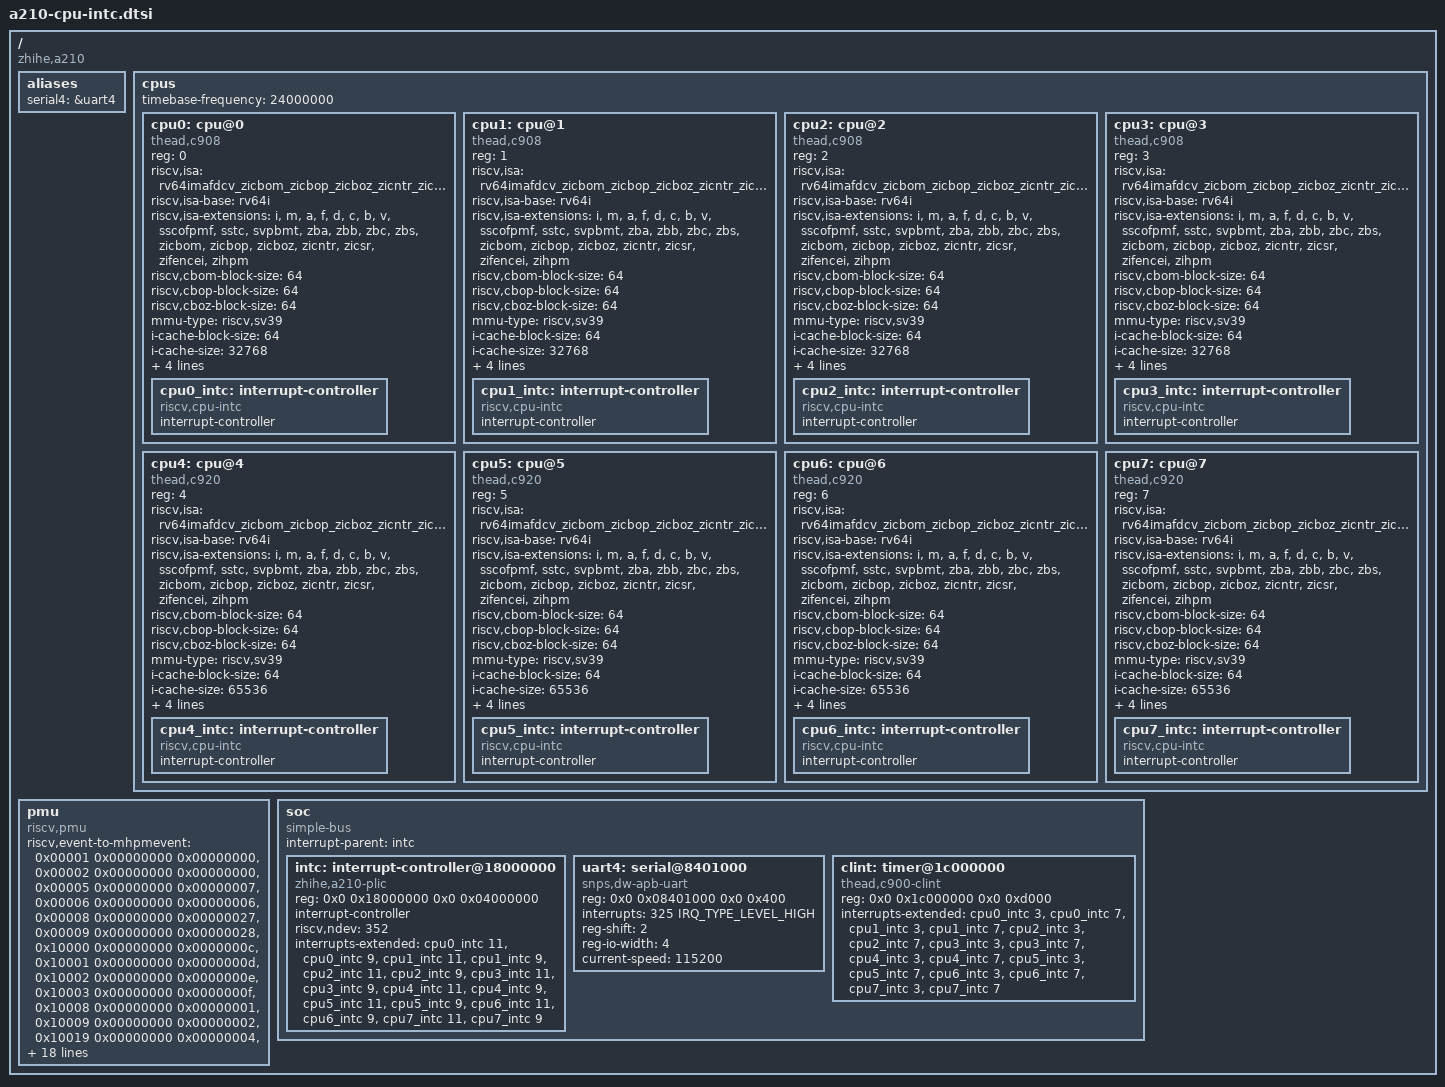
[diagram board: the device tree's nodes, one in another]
// SPDX-License-Identifier: (GPL-2.0-only OR BSD-2-Clause)
/*
 * Common A210 CPU/interrupt description for U-Boot and OpenSBI.
 * Hardware values follow the A210 Linux DTS; bootph tags are U-Boot-only.
 */
#include <dt-bindings/interrupt-controller/irq.h>

/ {
	compatible = "zhihe,a210";
	#address-cells = <2>;
	#size-cells = <2>;

	aliases {
		serial4 = &uart4;
	};

	cpus: cpus {
		#address-cells = <1>;
		#size-cells = <0>;
		timebase-frequency = <24000000>;
		bootph-pre-ram;

		cpu0: cpu@0 {
			device_type = "cpu";
			reg = <0>;
			compatible = "thead,c908", "riscv";
			/* Legacy U-Boot CPU code still reads riscv,isa. */
			riscv,isa = "rv64imafdcv_zicbom_zicbop_zicboz_zicntr_zicsr_zifencei_zihpm_zba_zbb_zbc_zbs_sscofpmf_sstc_svpbmt";
			riscv,isa-base = "rv64i";
			riscv,isa-extensions = "i", "m", "a", "f", "d", "c", "b", "v",
				"sscofpmf", "sstc", "svpbmt", "zba", "zbb", "zbc", "zbs",
				"zicbom", "zicbop", "zicboz", "zicntr", "zicsr",
				"zifencei", "zihpm";
			riscv,cbom-block-size = <64>;
			riscv,cbop-block-size = <64>;
			riscv,cboz-block-size = <64>;
			mmu-type = "riscv,sv39";
			i-cache-block-size = <64>;
			i-cache-size = <32768>;
			i-cache-sets = <256>;
			d-cache-block-size = <64>;
			d-cache-size = <32768>;
			d-cache-sets = <256>;
			status = "okay";
			bootph-pre-ram;

			cpu0_intc: interrupt-controller {
				compatible = "riscv,cpu-intc";
				#interrupt-cells = <1>;
				interrupt-controller;
				bootph-pre-ram;
			};
		};

		cpu1: cpu@1 {
			device_type = "cpu";
			reg = <1>;
			compatible = "thead,c908", "riscv";
			/* Legacy U-Boot CPU code still reads riscv,isa. */
			riscv,isa = "rv64imafdcv_zicbom_zicbop_zicboz_zicntr_zicsr_zifencei_zihpm_zba_zbb_zbc_zbs_sscofpmf_sstc_svpbmt";
			riscv,isa-base = "rv64i";
			riscv,isa-extensions = "i", "m", "a", "f", "d", "c", "b", "v",
				"sscofpmf", "sstc", "svpbmt", "zba", "zbb", "zbc", "zbs",
				"zicbom", "zicbop", "zicboz", "zicntr", "zicsr",
				"zifencei", "zihpm";
			riscv,cbom-block-size = <64>;
			riscv,cbop-block-size = <64>;
			riscv,cboz-block-size = <64>;
			mmu-type = "riscv,sv39";
			i-cache-block-size = <64>;
			i-cache-size = <32768>;
			i-cache-sets = <256>;
			d-cache-block-size = <64>;
			d-cache-size = <32768>;
			d-cache-sets = <256>;
			status = "okay";
			bootph-pre-ram;

			cpu1_intc: interrupt-controller {
				compatible = "riscv,cpu-intc";
				#interrupt-cells = <1>;
				interrupt-controller;
				bootph-pre-ram;
			};
		};

		cpu2: cpu@2 {
			device_type = "cpu";
			reg = <2>;
			compatible = "thead,c908", "riscv";
			/* Legacy U-Boot CPU code still reads riscv,isa. */
			riscv,isa = "rv64imafdcv_zicbom_zicbop_zicboz_zicntr_zicsr_zifencei_zihpm_zba_zbb_zbc_zbs_sscofpmf_sstc_svpbmt";
			riscv,isa-base = "rv64i";
			riscv,isa-extensions = "i", "m", "a", "f", "d", "c", "b", "v",
				"sscofpmf", "sstc", "svpbmt", "zba", "zbb", "zbc", "zbs",
				"zicbom", "zicbop", "zicboz", "zicntr", "zicsr",
				"zifencei", "zihpm";
			riscv,cbom-block-size = <64>;
			riscv,cbop-block-size = <64>;
			riscv,cboz-block-size = <64>;
			mmu-type = "riscv,sv39";
			i-cache-block-size = <64>;
			i-cache-size = <32768>;
			i-cache-sets = <256>;
			d-cache-block-size = <64>;
			d-cache-size = <32768>;
			d-cache-sets = <256>;
			status = "okay";
			bootph-pre-ram;

			cpu2_intc: interrupt-controller {
				compatible = "riscv,cpu-intc";
				#interrupt-cells = <1>;
				interrupt-controller;
				bootph-pre-ram;
			};
		};

		cpu3: cpu@3 {
			device_type = "cpu";
			reg = <3>;
			compatible = "thead,c908", "riscv";
			/* Legacy U-Boot CPU code still reads riscv,isa. */
			riscv,isa = "rv64imafdcv_zicbom_zicbop_zicboz_zicntr_zicsr_zifencei_zihpm_zba_zbb_zbc_zbs_sscofpmf_sstc_svpbmt";
			riscv,isa-base = "rv64i";
			riscv,isa-extensions = "i", "m", "a", "f", "d", "c", "b", "v",
				"sscofpmf", "sstc", "svpbmt", "zba", "zbb", "zbc", "zbs",
				"zicbom", "zicbop", "zicboz", "zicntr", "zicsr",
				"zifencei", "zihpm";
			riscv,cbom-block-size = <64>;
			riscv,cbop-block-size = <64>;
			riscv,cboz-block-size = <64>;
			mmu-type = "riscv,sv39";
			i-cache-block-size = <64>;
			i-cache-size = <32768>;
			i-cache-sets = <256>;
			d-cache-block-size = <64>;
			d-cache-size = <32768>;
			d-cache-sets = <256>;
			status = "okay";
			bootph-pre-ram;

			cpu3_intc: interrupt-controller {
				compatible = "riscv,cpu-intc";
				#interrupt-cells = <1>;
				interrupt-controller;
				bootph-pre-ram;
			};
		};

		cpu4: cpu@4 {
			device_type = "cpu";
			reg = <4>;
			compatible = "thead,c920", "riscv";
			/* Legacy U-Boot CPU code still reads riscv,isa. */
			riscv,isa = "rv64imafdcv_zicbom_zicbop_zicboz_zicntr_zicsr_zifencei_zihpm_zba_zbb_zbc_zbs_sscofpmf_sstc_svpbmt";
			riscv,isa-base = "rv64i";
			riscv,isa-extensions = "i", "m", "a", "f", "d", "c", "b", "v",
				"sscofpmf", "sstc", "svpbmt", "zba", "zbb", "zbc", "zbs",
				"zicbom", "zicbop", "zicboz", "zicntr", "zicsr",
				"zifencei", "zihpm";
			riscv,cbom-block-size = <64>;
			riscv,cbop-block-size = <64>;
			riscv,cboz-block-size = <64>;
			mmu-type = "riscv,sv39";
			i-cache-block-size = <64>;
			i-cache-size = <65536>;
			i-cache-sets = <512>;
			d-cache-block-size = <64>;
			d-cache-size = <65536>;
			d-cache-sets = <512>;
			status = "okay";
			bootph-pre-ram;

			cpu4_intc: interrupt-controller {
				compatible = "riscv,cpu-intc";
				#interrupt-cells = <1>;
				interrupt-controller;
				bootph-pre-ram;
			};
		};

		cpu5: cpu@5 {
			device_type = "cpu";
			reg = <5>;
			compatible = "thead,c920", "riscv";
			/* Legacy U-Boot CPU code still reads riscv,isa. */
			riscv,isa = "rv64imafdcv_zicbom_zicbop_zicboz_zicntr_zicsr_zifencei_zihpm_zba_zbb_zbc_zbs_sscofpmf_sstc_svpbmt";
			riscv,isa-base = "rv64i";
			riscv,isa-extensions = "i", "m", "a", "f", "d", "c", "b", "v",
				"sscofpmf", "sstc", "svpbmt", "zba", "zbb", "zbc", "zbs",
				"zicbom", "zicbop", "zicboz", "zicntr", "zicsr",
				"zifencei", "zihpm";
			riscv,cbom-block-size = <64>;
			riscv,cbop-block-size = <64>;
			riscv,cboz-block-size = <64>;
			mmu-type = "riscv,sv39";
			i-cache-block-size = <64>;
			i-cache-size = <65536>;
			i-cache-sets = <512>;
			d-cache-block-size = <64>;
			d-cache-size = <65536>;
			d-cache-sets = <512>;
			status = "okay";
			bootph-pre-ram;

			cpu5_intc: interrupt-controller {
				compatible = "riscv,cpu-intc";
				#interrupt-cells = <1>;
				interrupt-controller;
				bootph-pre-ram;
			};
		};

		cpu6: cpu@6 {
			device_type = "cpu";
			reg = <6>;
			compatible = "thead,c920", "riscv";
			/* Legacy U-Boot CPU code still reads riscv,isa. */
			riscv,isa = "rv64imafdcv_zicbom_zicbop_zicboz_zicntr_zicsr_zifencei_zihpm_zba_zbb_zbc_zbs_sscofpmf_sstc_svpbmt";
			riscv,isa-base = "rv64i";
			riscv,isa-extensions = "i", "m", "a", "f", "d", "c", "b", "v",
				"sscofpmf", "sstc", "svpbmt", "zba", "zbb", "zbc", "zbs",
				"zicbom", "zicbop", "zicboz", "zicntr", "zicsr",
				"zifencei", "zihpm";
			riscv,cbom-block-size = <64>;
			riscv,cbop-block-size = <64>;
			riscv,cboz-block-size = <64>;
			mmu-type = "riscv,sv39";
			i-cache-block-size = <64>;
			i-cache-size = <65536>;
			i-cache-sets = <512>;
			d-cache-block-size = <64>;
			d-cache-size = <65536>;
			d-cache-sets = <512>;
			status = "okay";
			bootph-pre-ram;

			cpu6_intc: interrupt-controller {
				compatible = "riscv,cpu-intc";
				#interrupt-cells = <1>;
				interrupt-controller;
				bootph-pre-ram;
			};
		};

		cpu7: cpu@7 {
			device_type = "cpu";
			reg = <7>;
			compatible = "thead,c920", "riscv";
			/* Legacy U-Boot CPU code still reads riscv,isa. */
			riscv,isa = "rv64imafdcv_zicbom_zicbop_zicboz_zicntr_zicsr_zifencei_zihpm_zba_zbb_zbc_zbs_sscofpmf_sstc_svpbmt";
			riscv,isa-base = "rv64i";
			riscv,isa-extensions = "i", "m", "a", "f", "d", "c", "b", "v",
				"sscofpmf", "sstc", "svpbmt", "zba", "zbb", "zbc", "zbs",
				"zicbom", "zicbop", "zicboz", "zicntr", "zicsr",
				"zifencei", "zihpm";
			riscv,cbom-block-size = <64>;
			riscv,cbop-block-size = <64>;
			riscv,cboz-block-size = <64>;
			mmu-type = "riscv,sv39";
			i-cache-block-size = <64>;
			i-cache-size = <65536>;
			i-cache-sets = <512>;
			d-cache-block-size = <64>;
			d-cache-size = <65536>;
			d-cache-sets = <512>;
			status = "okay";
			bootph-pre-ram;

			cpu7_intc: interrupt-controller {
				compatible = "riscv,cpu-intc";
				#interrupt-cells = <1>;
				interrupt-controller;
				bootph-pre-ram;
			};
		};
	};

	pmu {
		compatible = "riscv,pmu";
		riscv,event-to-mhpmevent =
			/* PMU_HW_CPU_CYCLES:1 */
			<0x00001 0x00000000 0x00000000>,
			/* PMU_HW_INSTRUCTIONS:2 */
			<0x00002 0x00000000 0x00000000>,
			/* PMU_HW_CACHE_REFERENCES:3 */
			/* PMU_HW_CACHE_MISSES:4 */
			/* PMU_HW_BRANCH_INSTRUCTIONS:5 */
			<0x00005 0x00000000 0x00000007>,
			/* PMU_HW_BRANCH_MISSES:6 */
			<0x00006 0x00000000 0x00000006>,
			/* PMU_HW_BUS_CYCLES:7 */
			/* PMU_HW_STALLED_CYCLES_FRONTEND:8 */
			<0x00008 0x00000000 0x00000027>,
			/* PMU_HW_STALLED_CYCLES_BACKEND:9 */
			<0x00009 0x00000000 0x00000028>,
			/* PMU_HW_REF_CPU_CYCLES:10 */
			/* L1D_READ_ACCESS:0x10000 */
			<0x10000 0x00000000 0x0000000c>,
			/* L1D_READ_MISS:0x10001 */
			<0x10001 0x00000000 0x0000000d>,
			/* L1D_WRITE_ACCESS:0x10002 */
			<0x10002 0x00000000 0x0000000e>,
			/* L1D_WRITE_MISS:0x10003 */
			<0x10003 0x00000000 0x0000000f>,
			/* L1I_READ_ACCESS:0x10008 */
			<0x10008 0x00000000 0x00000001>,
			/* L1I_READ_MISS:0x10009 */
			<0x10009 0x00000000 0x00000002>,
			/* dTLB read miss :0x10019 */
			<0x10019 0x00000000 0x00000004>,
			/* iTLB read miss :0x10021 */
			<0x10021 0x00000000 0x00000003>;
			/* LL_READ_ACCESS:0x10010 */
			/* LL_READ_MISS:0x10011 */
			/* LL_WRITE_ACCESS:0x10012 */
			/* LL_WRITE_MISS:0x10013 */
			/* BPU_READ_ACCESS:0x10028 */
			/* BPU_READ_MISS:0x10029 */
		riscv,event-to-mhpmcounters =
			/* 31 mhpmcounters, bitmap 0xfffffff8 */
			<0x00001 0x00001 0x00000001>,
			<0x00002 0x00002 0x00000004>,
			<0x00005 0x00005 0xfffffff8>,
			<0x00006 0x00006 0xfffffff8>,
			<0x00008 0x00008 0xfffffff8>,
			<0x00009 0x00009 0xfffffff8>,
			<0x10000 0x10000 0xfffffff8>,
			<0x10001 0x10001 0xfffffff8>,
			<0x10002 0x10002 0xfffffff8>,
			<0x10003 0x10003 0xfffffff8>,
			<0x10008 0x10008 0xfffffff8>,
			<0x10009 0x10009 0xfffffff8>,
			<0x10019 0x10019 0xfffffff8>,
			<0x10021 0x10021 0xfffffff8>;
		riscv,raw-event-to-mhpmcounters =
			/* For raw event ID 0x0 - 0xff */
			<0x0 0x0 0xffffffff 0xffffff00 0xfffffff8>;
	};

	soc {
		compatible = "simple-bus";
		#address-cells = <2>;
		#size-cells = <2>;
		interrupt-parent = <&intc>;
		ranges;

		intc: interrupt-controller@18000000 {
			compatible = "zhihe,a210-plic", "thead,c900-plic";
			reg = <0x0 0x18000000 0x0 0x04000000>;
			#address-cells = <0>;
			#interrupt-cells = <2>;
			interrupt-controller;
			riscv,ndev = <352>;
			interrupts-extended = <&cpu0_intc 11>, <&cpu0_intc 9>,
					      <&cpu1_intc 11>, <&cpu1_intc 9>,
					      <&cpu2_intc 11>, <&cpu2_intc 9>,
					      <&cpu3_intc 11>, <&cpu3_intc 9>,
					      <&cpu4_intc 11>, <&cpu4_intc 9>,
					      <&cpu5_intc 11>, <&cpu5_intc 9>,
					      <&cpu6_intc 11>, <&cpu6_intc 9>,
					      <&cpu7_intc 11>, <&cpu7_intc 9>;
			bootph-pre-ram;
		};

		uart4: serial@8401000 {
			compatible = "snps,dw-apb-uart";
			reg = <0x0 0x08401000 0x0 0x400>;
			interrupts = <325 IRQ_TYPE_LEVEL_HIGH>;
			reg-shift = <2>;
			reg-io-width = <4>;
			current-speed = <115200>;
			bootph-pre-ram;
		};

		clint: timer@1c000000 {
			compatible = "thead,c900-clint";
			reg = <0x0 0x1c000000 0x0 0xd000>;
			interrupts-extended = <&cpu0_intc 3>, <&cpu0_intc 7>,
					      <&cpu1_intc 3>, <&cpu1_intc 7>,
					      <&cpu2_intc 3>, <&cpu2_intc 7>,
					      <&cpu3_intc 3>, <&cpu3_intc 7>,
					      <&cpu4_intc 3>, <&cpu4_intc 7>,
					      <&cpu5_intc 3>, <&cpu5_intc 7>,
					      <&cpu6_intc 3>, <&cpu6_intc 7>,
					      <&cpu7_intc 3>, <&cpu7_intc 7>;
			bootph-pre-ram;
		};
	};
};
